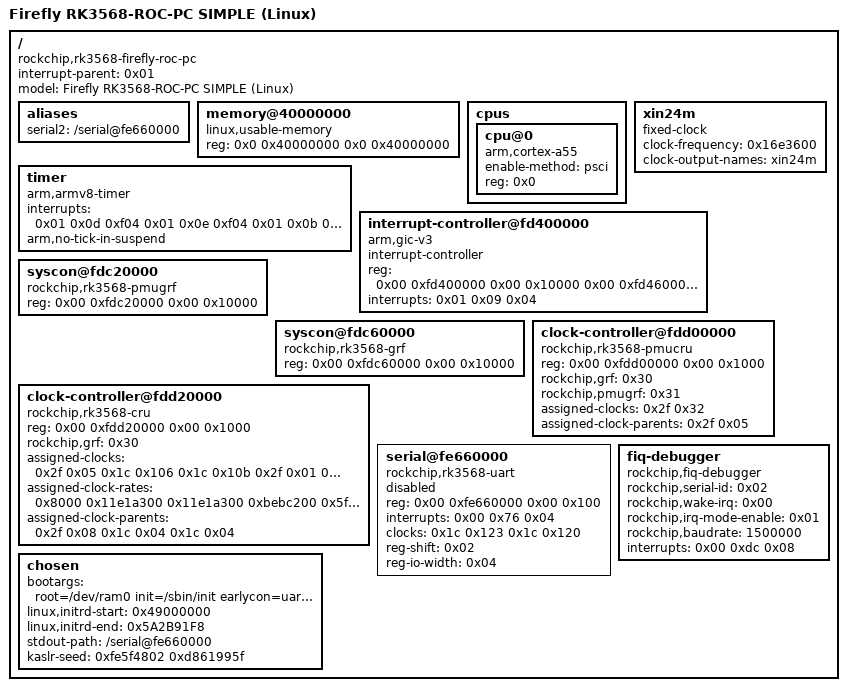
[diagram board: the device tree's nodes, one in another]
/dts-v1/;

/ {
	compatible = "rockchip,rk3568-firefly-roc-pc\0rockchip,rk3568";
	interrupt-parent = <0x01>;
	#address-cells = <0x02>;
	#size-cells = <0x02>;
	model = "Firefly RK3568-ROC-PC SIMPLE (Linux)";

	aliases {
		serial2 = "/serial@fe660000";
	};

	memory@40000000 {
		compatible = "linux,usable-memory";
		device_type = "memory";
		reg = <0x0 0x40000000 0x0 0x40000000>;
	};

	cpus {
		#address-cells = <1>;
		#size-cells = <0>;

		cpu@0 {
			device_type = "cpu";
			compatible = "arm,cortex-a55";
			enable-method = "psci";
			reg = <0x0>;
		};
	};

	timer {
		compatible = "arm,armv8-timer";
		interrupts = <0x01 0x0d 0xf04 0x01 0x0e 0xf04 0x01 0x0b 0xf04 0x01 0x0a 0xf04>;
		arm,no-tick-in-suspend;
	};

	xin24m {
		compatible = "fixed-clock";
		#clock-cells = <0x00>;
		clock-frequency = <0x16e3600>;
		clock-output-names = "xin24m";
		phandle = <0x160>;
	};

	interrupt-controller@fd400000 {
		compatible = "arm,gic-v3";
		#interrupt-cells = <0x03>;
		#address-cells = <0x02>;
		#size-cells = <0x02>;
		ranges;
		interrupt-controller;
		reg = <0x00 0xfd400000 0x00 0x10000 0x00 0xfd460000 0x00 0xc0000>;
		interrupts = <0x01 0x09 0x04>;
		phandle = <0x01>;
	};

	/* system configure space(pmugrf), do not delete */
	syscon@fdc20000 {
		compatible = "rockchip,rk3568-pmugrf\0syscon\0simple-mfd";
		reg = <0x00 0xfdc20000 0x00 0x10000>;
		phandle = <0x31>;
	};
	/* system configure space(grf), do not delete */
	syscon@fdc60000 {
		compatible = "rockchip,rk3568-grf\0syscon\0simple-mfd";
		reg = <0x00 0xfdc60000 0x00 0x10000>;
		phandle = <0x30>;
	};

	/* system clock controler(pmucru) */
	clock-controller@fdd00000 {
		compatible = "rockchip,rk3568-pmucru";
		reg = <0x00 0xfdd00000 0x00 0x1000>;
		rockchip,grf = <0x30>;
		rockchip,pmugrf = <0x31>;
		#clock-cells = <0x01>;
		#reset-cells = <0x01>;
		assigned-clocks = <0x2f 0x32>;
		assigned-clock-parents = <0x2f 0x05>;
		phandle = <0x2f>;
	};
	/* system clock controler(cru) */
	clock-controller@fdd20000 {
		compatible = "rockchip,rk3568-cru";
		reg = <0x00 0xfdd20000 0x00 0x1000>;
		rockchip,grf = <0x30>;
		#clock-cells = <0x01>;
		#reset-cells = <0x01>;
		assigned-clocks = <0x2f 0x05 0x1c 0x106 0x1c 0x10b 0x2f 0x01 0x2f 0x2b 0x1c 0x03 0x1c 0x19b 0x1c 0x09 0x1c 0x19c 0x1c 0x19d 0x1c 0x1a1 0x1c 0x19e 0x1c 0x19f 0x1c 0x1a0 0x1c 0x04 0x1c 0x10d 0x1c 0x10e 0x1c 0x173 0x1c 0x174 0x1c 0x175 0x1c 0x176 0x1c 0xc9 0x1c 0xca 0x1c 0x06 0x1c 0x7e 0x1c 0x7f 0x1c 0x3d 0x1c 0x41 0x1c 0x45 0x1c 0x49 0x1c 0x4d 0x1c 0x4d 0x1c 0x55 0x1c 0x51 0x1c 0x5d 0x1c 0xdd>;
		assigned-clock-rates = <0x8000 0x11e1a300 0x11e1a300 0xbebc200 0x5f5e100 0x3b9aca00 0x1dcd6500 0x13d92d40 0xee6b280 0x7735940 0x5f5e100 0x3b9aca0 0x2faf080 0x17d7840 0x46cf7100 0x8f0d180 0x5f5e100 0x1dcd6500 0x17d78400 0x8f0d180 0x5f5e100 0x11e1a300 0x8f0d180 0x47868c00 0x17d78400 0x5f5e100 0x46cf7100 0x46cf7100 0x46cf7100 0x46cf7100 0x46cf7100 0x46cf7100 0x46cf7100 0x46cf7100 0x46cf7100 0x1dcd6500>;
		assigned-clock-parents = <0x2f 0x08 0x1c 0x04 0x1c 0x04>;
		phandle = <0x1c>;
	};

	serial@fe660000 {
		compatible = "rockchip,rk3568-uart\0snps,dw-apb-uart";
		reg = <0x00 0xfe660000 0x00 0x100>;
		interrupts = <0x00 0x76 0x04>;
		clocks = <0x1c 0x123 0x1c 0x120>;
		clock-names = "baudclk\0apb_pclk";
		reg-shift = <0x02>;
		reg-io-width = <0x04>;
		status = "disable";
		phandle = <0x1d0>;
	};

	fiq-debugger {
		compatible = "rockchip,fiq-debugger";
		rockchip,serial-id = <0x02>;
		rockchip,wake-irq = <0x00>;
		rockchip,irq-mode-enable = <0x01>;
		rockchip,baudrate = <1500000>;
		interrupts = <0x00 0xdc 0x08>;
		status = "okay";
	};

	__symbols__ {
		xin24m = "/xin24m";
		gic = "/interrupt-controller@fd400000";
		pmugrf = "/syscon@fdc20000";
		grf = "/syscon@fdc60000";
		pmucru = "/clock-controller@fdd00000";
		cru = "/clock-controller@fdd20000";
		uart2 = "/serial@fe660000";
	};

	chosen {
		bootargs = "root=/dev/ram0 init=/sbin/init earlycon=uart8250,mmio32,0xfe660000 console=ttyFIQ0 ramdisk_size=10000000 rootfstype=cpio rw";
		linux,initrd-start = <0x49000000>;
		linux,initrd-end = <0x5A2B91F8>;
		stdout-path = "/serial@fe660000";
		kaslr-seed = <0xfe5f4802 0xd861995f>;
	};

};
